# AE402FA0E5597LE0_CM55_HE_View register map
Vendor: Alif Semiconductor; Series: E4; File version: 1.0
CPU: CM55 r1p0, selectable endian, MPU, FPU, double-precision FPU, DSP, VTOR, 8 interrupt priority bits, 1 SAU regions
Registers are 32-bit, read-write, reset 0x0 unless marked. A register's access mark holds for its fields unless they carry their own. Offsets are from the block's base; [hi:lo] are bit positions; 'fields as' and 'values as' point back to an identical list.

## LPI2C1
Base 0x43005000
Same registers: I2C0 0x49010000, I2C1 0x49011000, I2C2 0x49012000, I2C3 0x49013000
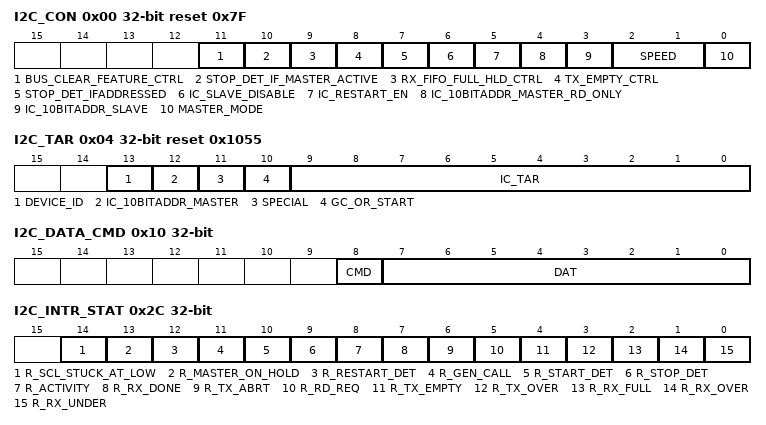
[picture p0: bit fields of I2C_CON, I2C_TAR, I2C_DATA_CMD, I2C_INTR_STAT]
0x00 I2C_CON reset 0x7F — Control Register
  [11] BUS_CLEAR_FEATURE_CTRL — In master mode: In slave mode, this bit is not applicable.
    0=Bus clear feature is disabled; 1=Bus clear feature is enabled
  [10] STOP_DET_IF_MASTER_ACTIVE ro — In master mode, this bit controls whether the I2C issues the STOP_DET interrupt only when master is active or always.
    0=Master issues the STOP_DET interrupt regardless of whether it is active or not; 1=Master issues the STOP_DET interrupt only when active
  [9] RX_FIFO_FULL_HLD_CTRL ro — This bit controls whether the I2C holds the bus when the Rx FIFO is completely full (until data is read out and there is space available in the buffer), or if the Rx FIFO overflows.
    0=Overflow when RX_FIFO is full; 1=Hold bus when RX_FIFO is full
  [8] TX_EMPTY_CTRL — This bit controls the generation of the TX_EMPTY interrupt, as described in the I2C_RAW_INTR_STAT[TX_EMPTY] bit field.
    0=Default behaviour of TX_EMPTY interrupt; 1=Controlled generation of TX_EMPTY interrupt
  [7] STOP_DET_IFADDRESSED — In slave mode, this bit controls whether the I2C issues the STOP_DET interrupt only when slave is addressed or always. Note: During a General Call address, the I2C slave does not issue the STOP_DET interrupt if STOP_DET_IFADDRESSED = 1, even if the I2C slave responds to the General Call address by generating an ACK. The STOP_DET interrupt is issued only when the transmitted address matches the I2C slave address (I2C_SAR).
    0=Slave issues the STOP_DET interrupt regardless of whether it is addressed or not; 1=Slave issues the STOP_DET interrupt only when addressed
  [6] IC_SLAVE_DISABLE — This bit controls whether the I2C has its slave mode enabled or disabled. At reset, I2C slave mode is disabled. Note: Software should ensure that, if this bit is set to 0, then the MASTER_MODE bit is also set to 0 (to ensure proper operation in slave mode).
    0=Slave mode is enabled; 1=Slave mode is disabled
  [5] IC_RESTART_EN — Determines whether RESTART conditions may be sent when acting as a master. Some older slaves do not support handling RESTART conditions; however, RESTART conditions are used in several I2C operations. When RESTART is disabled, the master is prohibited from performing the following functions: - Sending a START BYTE - Performing any high-speed mode operation - Performing direction changes in combined format mode - Performing a read operation with a 10-bit address By replacing RESTART condition followed by STOP and subsequent START condition, split operations are broken down into multiple I2C transfers. If the above operations are performed, it will result in asserting the I2C_RAW_INTR_STAT[TX_ABRT] bit.
    0=Master restart disabled; 1=Master restart enabled
  [4] IC_10BITADDR_MASTER_RD_ONLY ro — For I2C[0-3]: This bit is named IC_10BITADDR_MASTER_RD_ONLY. The function of this bit is handled by the corresponding bit [12] IC_10BITADDR_MASTER in the I2C_TAR register, so this bit is just a read-only copy. For LPI2C1: This bit is named IC_10BITADDR_MASTER. It controls whether the I2C starts its transfers in 7- or 10-bit addressing mode when acting as a master. NOTE: Access type is: R for I2C[0-3]; R/W for LPI2C1.
    0=7-bit master addressing mode; 1=10-bit master addressing mode
  [3] IC_10BITADDR_SLAVE — When acting as a slave, this bit controls whether the I2C responds to 7-bit or 10-bit addresses.
    0=7-bit slave addressing mode. The I2C ignores transactions that involve 10-bit addressing; only the lower 7 bits of I2C_SAR register are compared.; 1=10-bit slave addressing mode. The I2C responds only to 10-bit addressing transfers that match the full 10 bits of I2C_SAR register.
  [2:1] SPEED — These bits control at which speed the I2C operates; its setting is relevant only if the I2C operates in Master mode. Hardware protects against illegal values being programmed by software. These bits must be programmed appropriately for Slave mode also, as they are used to capture correct value of spike filter as per the speed mode. This register should be programmed only with a value in the range of 1 to 3.
    1=Standard mode of operation; 2=Fast or Fast Plus mode of operation; 3=High-speed mode of operation
  [0] MASTER_MODE — This bit controls whether the I2C has its master mode enabled or disabled. At reset, I2C master mode is enabled. Note: Software should ensure that, if this bit is set to 1, then the IC_SLAVE_DISABLE bit is also set to 1 (to ensure proper operation in master mode).
    0=Master mode is disabled; 1=Master mode is enabled
0x04 I2C_TAR reset 0x1055 — Target Address Register
  [13] DEVICE_ID — If bit [11] SPECIAL = 1, then this bit controls whether a Device-ID transfer of a particular slave targeted in the [9-0] IC_TAR field is to be performed by the I2C master.
    0=Disables programming of Device-ID transmission. A Device-ID transfer is not performed and I2C checks bit [10] GC_OR_START to perform either a General Call, or a START BYTE command.; 1=Enables programming of Device-ID transmission. A Device-ID transfer is performed and data bytes based on the number of read commands in the Tx FIFO are received from the targeted slave and put in the Rx FIFO.
  [12] IC_10BITADDR_MASTER — For I2C[0-3]: This bit is named IC_10BITADDR_MASTER. It controls whether the I2C starts its transfers in 7-bit or 10-bit addressing mode, when acting as a master. For LPI2C1: This bit is named IC_10BITADDR_MASTER_RD_ONLY. The function of this bit is handled by the corresponding bit [4] IC_10BITADDR_MASTER in the I2C_CON register, so this bit is just a read-only copy. NOTE: Access type is: R/W for I2C[0-3]; R for LPI2C1.
    values as I2C_CON.IC_10BITADDR_MASTER_RD_ONLY
  [11] SPECIAL — This bit controls whether software performs a special command: Device-ID, or General Call, or START BYTE.
    0=Disables programming of special I2C command. I2C ignores bit [13] DEVICE_ID and bit [10] GC_OR_START and uses the [9-0] IC_TAR field normally.; 1=Enables programming of special I2C command. I2C performs a special command as specified in bit [13] DEVICE_ID or bit [10] GC_OR_START.
  [10] GC_OR_START — If bit [11] SPECIAL = 1 and bit [13] DEVICE_ID = 0, then this bit controls whether I2C performs a General Call or a START BYTE command. Note: After issuing a General Call, only writes may be performed. Attempting to issue a read command results in setting I2C_RAW_INTR_STAT[TX_ABRT] bit. The I2C remains in General Call mode until the SPECIAL bit value is cleared.
    0=General Call transmission; 1=START BYTE transmission
  [9:0] IC_TAR — This is the target address for any I2C master transaction. When transmitting a General Call, these bits are ignored. To generate a START BYTE command, the CPU needs to write into these bits only once. If I2C_TAR[IC_TAR] and I2C_SAR[IC_SAR] are the same, loopback exists but the FIFOs are shared between master and slave, so full loopback is not feasible. Only one direction loopback mode is supported (simplex); duplex is not supported. A master cannot transmit to itself; it can only transmit to a slave. Note: The correct operation of the I2C interface is not guaranteed if this field is programmed to any of the reserved values listed in Table 1-7.
0x08 I2C_SAR reset 0x55 — Slave Address Register
  [9:0] IC_SAR — This register holds the slave address when the I2C is operating as a slave. For 7-bit addressing, only bits [6-0] are used. This register can only be written when the I2C module is disabled, which corresponds to the I2C_ENABLE[ENABLE] bit being set to 0. Writes at other times have no effect. Note: The correct operation of the I2C interface is not guaranteed if this field is programmed to any of the reserved values listed in Table 1-7.
0x0C I2C_HS_MADDR reset 0x1 — High Speed Master Mode Code Address Register
  [2:0] IC_HS_MAR — This bit field holds the value of the I2C HS mode master code. HS mode master codes are reserved 8-bit codes (00001xxx) that are not used for slave addressing or other purposes. Each master has its unique master code; up to eight high-speed mode masters can be present on the same I^2C bus system. Valid values are 0-7. This register can only be written when the I2C module is disabled, which corresponds to the I2C_ENABLE[ENABLE] bit being set to 0. Writes at other times have no effect.
0x10 I2C_DATA_CMD — Rx/Tx Data Buffer and Command Register
  [8] CMD wo — This bit controls whether a read or a write is performed. This bit does not control the direction of data transfer when I2C acts as a slave; it controls the direction only when I2C acts as a master. When a command is entered in the Tx FIFO, this bit distinguishes the write and read commands. In the slave-receiver mode, this bit is a 'don't care' because writes to this register are not required. In the slave-transmitter mode, a 0 in this bit indicates that the data in the [7-0] DAT field is to be transmitted. When programming this bit, consider the following: - Attempting to perform a read operation after sending a General Call command results in the TX_ABRT interrupt (I2C_RAW_INTR_STAT[TX_ABRT] bit) being asserted, unless the I2C_TAR[SPECIAL] bit has been cleared; - If a 1 is written to this bit after receiving RD_REQ interrupt, then TX_ABRT interrupt occurs.
    0=Master write command; 1=Master read command
  [7:0] DAT — This field contains the data to be transmitted or received on the I2C interface. If this field is written while bit [8] CMD = 1, it is ignored by the I2C. If this field is read while bit [8] CMD = 1, it returns the value of the data received on the I2C interface.
0x14 I2C_SS_SCL_HCNT reset 0x190 — Standard Speed SCL High Count Register
  [15:0] IC_SS_SCL_HCNT — This register must be set before any I2C bus transaction can take place to ensure proper I/O timing. It sets the SCL clock high period count for standard speed. This register can only be written when the I2C module is disabled, which corresponds to the I2C_ENABLE[ENABLE] bit being set to 0. Writes at other times have no effect. The minimum valid value is 6; hardware prevents values less than this being written, and if attempted, results in 6 being set. Note: This register must not be programmed to a value higher than 65525, because I2C uses a 16-bit counter to flag an I^2C bus IDLE condition when this counter reaches a value of I2C_SS_SCL_HCNT + 10.
0x18 I2C_SS_SCL_LCNT reset 0x1D6 — Standard Speed SCL Low Count Register
  [15:0] IC_SS_SCL_LCNT — This register must be set before any I2C bus transaction can take place to ensure proper I/O timing. This register sets the SCL clock low period count for standard speed. This register can only be written when the I2C module is disabled, which corresponds to the I2C_ENABLE[ENABLE] bit being set to 0. Writes at other times have no effect. The minimum valid value is 8; hardware prevents values less than this being written, and if attempted, results in 8 being set.
0x1C I2C_FS_SCL_HCNT reset 0x3C — Fast Speed or Fast Mode Plus SCL High Count Register
  [15:0] IC_FS_SCL_HCNT — This register must be set before any I2C bus transaction can take place to ensure proper I/O timing. This register sets the SCL clock high period count for fast speed or fast mode plus. This register can only be written when the I2C module is disabled, which corresponds to the I2C_ENABLE[ENABLE] bit being set to 0. Writes at other times have no effect. The minimum valid value is 6; hardware prevents values less than this being written, and if attempted, results in 6 being set.
0x20 I2C_FS_SCL_LCNT reset 0x82 — Fast Speed or Fast Mode Plus SCL Low Count Register
  [15:0] IC_FS_SCL_LCNT — This register must be set before any I2C bus transaction can take place to ensure proper I/O timing. This register sets the SCL clock low period count for fast speed or fast mode plus. This register can only be written when the I2C module is disabled, which corresponds to the I2C_ENABLE[ENABLE] bit being set to 0. Writes at other times have no effect. The minimum valid value is 8; hardware prevents values less than this being written, and if attempted, results in 8 being set.
0x24 I2C_HS_SCL_HCNT reset 0x6 — High Speed SCL High Count Register
  [15:0] IC_HS_SCL_HCNT — This register must be set before any I2C bus transaction can take place to ensure proper I/O timing. This register sets the SCL clock high period count for high speed. The SCL high time depends on the loading of the bus. For 100 pF loading, the SCL high time is 60 ns. This register can only be written when the I2C module is disabled, which corresponds to the I2C_ENABLE[ENABLE] bit being set to 0. Writes at other times have no effect. The minimum valid value is 6; hardware prevents values less than this being written, and if attempted, results in 6 being set.
0x28 I2C_HS_SCL_LCNT reset 0x10 — High Speed SCL Low Count Register
  [15:0] IC_HS_SCL_LCNT — This register must be set before any I2C bus transaction can take place to ensure proper I/O timing. This register sets the SCL clock low period count for high speed. The SCL low time depends on the loading of the bus. For 100 pF loading, the SCL low time is 160 ns. This register can only be written when the I2C module is disabled, which corresponds to the I2C_ENABLE[ENABLE] bit being set to 0. Writes at other times have no effect. The minimum valid value is 8; hardware prevents values less than this being written, and if attempted, results in 8 being set.
0x2C I2C_INTR_STAT ro — Interrupt Status Register
  [14] R_SCL_STUCK_AT_LOW — For details, see I2C_RAW_INTR_STAT[SCL_STUCK_AT_LOW].
    0=R_SCL_STUCK_AT_LOW interrupt is inactive; 1=R_SCL_STUCK_AT_LOW interrupt is active
  [13] R_MASTER_ON_HOLD — For details, see I2C_RAW_INTR_STAT[MASTER_ON_HOLD]. Note: This interrupt is not supported for LPI2C1 (no dynamic TAR update support).
    0=R_MASTER_ON_HOLD interrupt is inactive; 1=R_MASTER_ON_HOLD interrupt is active
  [12] R_RESTART_DET — For details, see I2C_RAW_INTR_STAT[RESTART_DET]. Note: This interrupt cannot be asserted in this device.
    0=R_RESTART_DET interrupt is inactive; 1=R_RESTART_DET interrupt is active
  [11] R_GEN_CALL — For details, see I2C_RAW_INTR_STAT[GEN_CALL].
    0=R_GEN_CALL interrupt is inactive; 1=R_GEN_CALL interrupt is active
  [10] R_START_DET — For details, see I2C_RAW_INTR_STAT[START_DET].
    0=R_START_DET interrupt is inactive; 1=R_START_DET interrupt is active
  [9] R_STOP_DET — For details, see I2C_RAW_INTR_STAT[STOP_DET].
    0=R_STOP_DET interrupt is inactive; 1=R_STOP_DET interrupt is active
  [8] R_ACTIVITY — For details, see I2C_RAW_INTR_STAT[ACTIVITY].
    0=R_ACTIVITY interrupt is inactive; 1=R_ACTIVITY interrupt is active
  [7] R_RX_DONE — For details, see I2C_RAW_INTR_STAT[RX_DONE].
    0=R_RX_DONE interrupt is inactive; 1=R_RX_DONE interrupt is active
  [6] R_TX_ABRT — For details, see I2C_RAW_INTR_STAT[TX_ABRT].
    0=R_TX_ABRT interrupt is inactive; 1=R_TX_ABRT interrupt is active
  [5] R_RD_REQ — For details, see I2C_RAW_INTR_STAT[RD_REQ].
    0=R_RD_REQ interrupt is inactive; 1=R_RD_REQ interrupt is active
  [4] R_TX_EMPTY — For details, see I2C_RAW_INTR_STAT[TX_EMPTY].
    0=R_TX_EMPTY interrupt is inactive; 1=R_TX_EMPTY interrupt is active
  [3] R_TX_OVER — For details, see I2C_RAW_INTR_STAT[TX_OVER].
    0=R_TX_OVER interrupt is inactive; 1=R_TX_OVER interrupt is active
  [2] R_RX_FULL — For details, see I2C_RAW_INTR_STAT[RX_FULL].
    0=R_RX_FULL interrupt is inactive; 1=R_RX_FULL interrupt is active
  [1] R_RX_OVER — For details, see I2C_RAW_INTR_STAT[RX_OVER].
    0=R_RX_OVER interrupt is inactive; 1=R_RX_OVER interrupt is active
  [0] R_RX_UNDER — For details, see I2C_RAW_INTR_STAT[RX_UNDER].
    0=R_RX_UNDER interrupt is inactive; 1=R_RX_UNDER interrupt is active
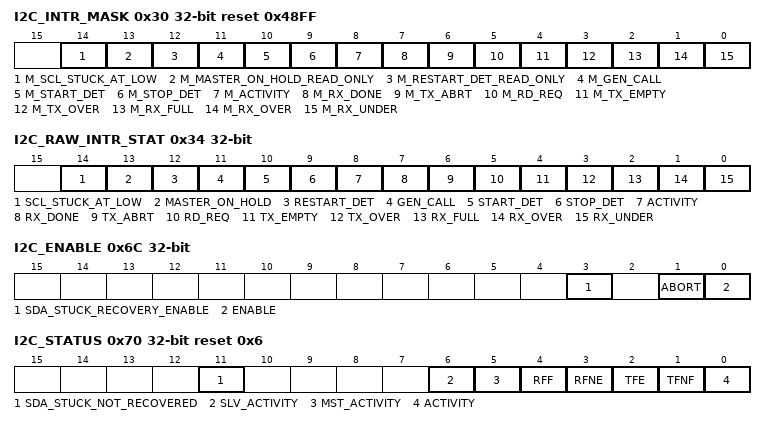
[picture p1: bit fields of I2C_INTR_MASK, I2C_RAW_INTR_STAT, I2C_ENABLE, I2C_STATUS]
0x30 I2C_INTR_MASK reset 0x48FF — Interrupt Mask Register
  [14] M_SCL_STUCK_AT_LOW — Masks the I2C_INTR_STAT[R_SCL_STUCK_AT_LOW] bit.
    0=SCL_STUCK_AT_LOW interrupt is masked; 1=SCL_STUCK_AT_LOW interrupt is unmasked
  [13] M_MASTER_ON_HOLD_READ_ONLY ro — Masks the I2C_INTR_STAT[R_MASTER_ON_HOLD] bit. Note: This interrupt is not supported for LPI2C1 (no dynamic TAR update support).
    0=MASTER_ON_HOLD interrupt is masked; 1=MASTER_ON_HOLD interrupt is unmasked
  [12] M_RESTART_DET_READ_ONLY ro — Masks the I2C_INTR_STAT[R_RESTART_DET] bit. Note: This interrupt cannot be enabled in this device.
    0=RESTART_DET interrupt is masked; 1=RESTART_DET interrupt is unmasked
  [11] M_GEN_CALL — Masks the I2C_INTR_STAT[R_GEN_CALL] bit.
    0=GEN_CALL interrupt is masked; 1=GEN_CALL interrupt is unmasked
  [10] M_START_DET — Masks the I2C_INTR_STAT[R_START_DET] bit.
    0=START_DET interrupt is masked; 1=START_DET interrupt is unmasked
  [9] M_STOP_DET — Masks the I2C_INTR_STAT[R_STOP_DET] bit.
    0=STOP_DET interrupt is masked; 1=STOP_DET interrupt is unmasked
  [8] M_ACTIVITY — Masks the I2C_INTR_STAT[R_ACTIVITY] bit.
    0=ACTIVITY interrupt is masked; 1=ACTIVITY interrupt is unmasked
  [7] M_RX_DONE — Masks the I2C_INTR_STAT[R_RX_DONE] bit.
    0=RX_DONE interrupt is masked; 1=RX_DONE interrupt is unmasked
  [6] M_TX_ABRT — Masks the I2C_INTR_STAT[R_TX_ABRT] bit.
    0=TX_ABRT interrupt is masked; 1=TX_ABRT interrupt is unmasked
  [5] M_RD_REQ — Masks the I2C_INTR_STAT[R_RD_REQ] bit.
    0=RD_REQ interrupt is masked; 1=RD_REQ interrupt is unmasked
  [4] M_TX_EMPTY — Masks the I2C_INTR_STAT[R_TX_EMPTY] bit.
    0=TX_EMPTY interrupt is masked; 1=TX_EMPTY interrupt is unmasked
  [3] M_TX_OVER — Masks the I2C_INTR_STAT [R_TX_OVER] bit.
    0=TX_OVER interrupt is masked; 1=TX_OVER interrupt is unmasked
  [2] M_RX_FULL — Masks the I2C_INTR_STAT[R_RX_FULL] bit.
    0=RX_FULL interrupt is masked; 1=RX_FULL interrupt is unmasked
  [1] M_RX_OVER — Masks the I2C_INTR_STAT[R_RX_OVER] bit.
    0=RX_OVER interrupt is masked; 1=RX_OVER interrupt is unmasked
  [0] M_RX_UNDER — Masks the I2C_INTR_STAT[R_RX_UNDER] bit.
    0=RX_UNDER interrupt is masked; 1=RX_UNDER interrupt is unmasked
0x34 I2C_RAW_INTR_STAT ro — Raw Interrupt Status Register
  [14] SCL_STUCK_AT_LOW — Indicates whether the SCL line is stuck at low for I2C_SCL_STUCK_AT_LOW_TIMEOUT number of IC_CLK periods.
    0=SCL_STUCK_AT_LOW interrupt is inactive; 1=SCL_STUCK_AT_LOW interrupt is active
  [13] MASTER_ON_HOLD — Indicates whether master is holding the bus and Tx FIFO is empty. Note: This interrupt is not supported for LPI2C1 (no dynamic TAR update support).
    0=MASTER_ON_HOLD interrupt is inactive; 1=MASTER_ON_HOLD interrupt is active
  [12] RESTART_DET — Indicates whether a RESTART condition has occurred on the I^2C interface when I2C is operating in slave mode and the slave is being addressed. Note: This interrupt cannot be set in this device.
    0=RESTART_DET interrupt is inactive; 1=RESTART_DET interrupt is active
  [11] GEN_CALL — This bit is set only when a General Call address is received and it is acknowledged. It stays set until it is cleared either by disabling I2C or when the CPU reads bit 0 of the I2C_CLR_GEN_CALL register. The I2C stores the received data in the Rx FIFO.
    0=GEN_CALL interrupt is inactive; 1=GEN_CALL interrupt is active
  [10] START_DET — Indicates whether a START or RESTART condition has occurred on the I2C interface regardless of whether I2C is operating in slave or master mode.
    0=START_DET interrupt is inactive; 1=START_DET interrupt is active
  [9] STOP_DET — Indicates whether a STOP condition has occurred on the I^2C interface regardless of whether I2C is operating in slave or master mode. In slave mode: - If I2C_CON[STOP_DET_IFADDRESSED] = 0, this interrupt is issued regardless of whether the I2C slave is addressed or not. - If I2C_CON[STOP_DET_IFADDRESSED] = 1, this interrupt is issued only if the I2C slave is addressed. Note: During a General Call address, the I2C slave does not issue the STOP_DET interrupt if STOP_DET_IFADDRESSED = 1, even if the I2C slave responds to the General Call address by generating an ACK. The STOP_DET interrupt is issued only when the transmitted address matches the I2C slave address (I2C_SAR). In master mode: - If I2C_CON[STOP_DET_IF_MASTER_ACTIVE] = 0, this interrupt is issued regardless of whether the I2C master is active or not. - If I2C_CON[STOP_DET_IF_MASTER_ACTIVE] = 1, this interrupt is issued only if the I2C master is active.
    0=STOP_DET interrupt is inactive; 1=STOP_DET interrupt is active
  [8] ACTIVITY — This bit captures I2C activity and stays set until it is cleared. There are four ways to clear it: - Disabling the I2C - Reading the I2C_CLR_ACTIVITY register - Reading the I2C_CLR_INTR register - System reset Once this bit is set, it stays set unless one of the four methods is used to clear it. Even if the I2C module is idle, this bit remains set until cleared, indicating that there was activity on the bus.
    0=RAW_INTR_ACTIVITY interrupt is inactive; 1=RAW_INTR_ACTIVITY interrupt is active
  [7] RX_DONE — When the I2C is acting as a slave-transmitter, this bit is set to 1 if the remote master does not acknowledge a transmitted byte. This occurs on the last byte of the transmission, indicating that the transmission is done.
    0=RX_DONE interrupt is inactive; 1=RX_DONE interrupt is active
  [6] TX_ABRT — This bit indicates if the I2C, acting as a transmitter on the I^2C bus, is unable to complete the intended actions on the contents of the Tx FIFO. This situation can occur both as an I^2C master or an I^2C slave, and is referred to as a transmit abort. When this bit is set to 1, the I2C_TX_ABRT_SOURCE register indicates the reason why the transmit abort has occured. The I2C flushes/resets/empties both the Tx FIFO and the Rx FIFO whenever there is a transmit abort caused by any of the events tracked by the I2C_TX_ABRT_SOURCE register. The FIFOs remain in this flushed state until the I2C_CLR_TX_ABRT register is read. Once this read is performed, the FIFOs are ready to accept more data bytes.
    0=TX_ABRT interrupt is inactive; 1=TX_ABRT interrupt is active
  [5] RD_REQ — This bit is set to 1 when the I2C is acting as a slave and another I^2C master is attempting to read data from I2C. The I2C holds the bus in a wait state until this interrupt is serviced, which means that the slave has been addressed by a remote master asking for data to be transferred. CPU must respond to this interrupt and then write the requested data to the I2C_DATA_CMD register. This bit is cleared just after the CPU reads the I2C_CLR_RD_REQ register.
    0=RD_REQ interrupt is inactive; 1=RD_REQ interrupt is active
  [4] TX_EMPTY — The behavior of the TX_EMPTY interrupt status differs based on the selection in the I2C_CON[TX_EMPTY_CTRL] bit. When I2C_CON[TX_EMPTY_CTRL] = 0: This bit is set to 1 when the transmit FIFO buffer is at or below the threshold value set in the I2C_TX_TL register. When I2C_CON[TX_EMPTY_CTRL] = 1: This bit is set to 1 when the transmit FIFO buffer is at or below the threshold value set in the I2C_TX_TL register and the transmission of the address/data from the internal shift register for the most recently popped command is completed. This bit is automatically cleared by hardware when the transmit buffer level goes above the threshold. If the module is disabled (I2C_ENABLE[ENABLE] = 0), the Tx FIFO is flushed and held in reset; therefore, the Tx FIFO looks like it has no data within it, so this bit is set to 1, provided there is activity in the master or slave state machines. When there is no longer any activity and I2C_ENABLE_STATUS[IC_EN] goes to 0, this bit is cleared.
    0=TX_EMPTY interrupt is inactive; 1=TX_EMPTY interrupt is active
  [3] TX_OVER — Set during transmit if the transmit buffer is completely full and the processor attempts to issue another I2C command by writing to the I2C_DATA_CMD register. If the module is disabled (I2C_ENABLE[ENABLE] = 0), this bit keeps its level until the master or slave state machines go into IDLE, and when the I2C_ENABLE_STATUS[IC_EN] bit goes to 0, this interrupt is cleared.
    0=TX_OVER interrupt is inactive; 1=TX_OVER interrupt is active
  [2] RX_FULL — Set when the receive buffer reaches or goes above the threshold level in the I2C_RX_TL register. This bit is automatically cleared by hardware when the receive buffer level goes below the threshold. If the module is disabled (I2C_ENABLE[ENABLE] = 0), the Rx FIFO is flushed and held in reset; therefore, the Rx FIFO is not full. So, this bit is cleared once the I2C_ENABLE[ENABLE] bit is programmed to 0, regardless of the activity that continues.
    0=RX_FULL interrupt is inactive; 1=RX_FULL interrupt is active
  [1] RX_OVER — Set if the receive buffer is completely full and an additional byte is received from an external I^2C device. The I2C acknowledges this, but any data bytes received after the Rx FIFO is full are lost. If the module is disabled (I2C_ENABLE[ENABLE] = 0), this bit keeps its level until the master or slave state machines go into IDLE, and when the I2C_ENABLE_STATUS[IC_EN] bit goes to 0, this interrupt is cleared.
    0=RX_OVER interrupt is inactive; 1=RX_OVER interrupt is active
  [0] RX_UNDER — Set if the processor attempts to read the receive buffer when it is empty by reading from the I2C_DATA_CMD register. If the module is disabled (I2C_ENABLE[ENABLE] = 0), this bit keeps its level until the master or slave state machines go into IDLE, and when the I2C_ENABLE_STATUS[IC_EN] bit goes to 0, this interrupt is cleared.
    0=RX_UNDER interrupt is inactive; 1=RX_UNDER interrupt is active
0x38 I2C_RX_TL — Receive FIFO Threshold Register
  [7:0] RX_TL — Controls the level of entries (or above) that triggers the RX_FULL interrupt (I2C_RAW_INTR_STAT[RX_FULL] bit). Valid range is 0-31 (Rx FIFO depth = 32). Hardware does not allow this field to be set to a value larger than the depth of the buffer; any attempt to do so results in a value of 31 being set. A value of 0 sets the threshold for 1 entry, and a value of 31 sets the threshold for 32 entries.
0x3C I2C_TX_TL — Transmit FIFO Threshold Register
  [7:0] TX_TL — Controls the level of entries (or below) that triggers the TX_EMPTY interrupt (I2C_RAW_INTR_STAT[TX_EMPTY]). Valid range is 0-31 (Tx FIFO depth = 32). Hardware does not allow this field to be set to a value larger than the depth of the buffer; any attempt to do so results in a value of 31 being set. A value of 0 sets the threshold for 0 entries, and a value of 31 sets the threshold for 31 entries.
0x40 I2C_CLR_INTR ro — Clear Combined and Individual Interrupt Register
  [0] CLR_INTR — Read this bit to: - Clear the combined interrupt; - Clear all individual interrupts; - Clear the I2C_TX_ABRT_SOURCE register; This bit does not clear hardware clearable interrupts but software clearable interrupts. Refer to I2C_TX_ABRT_SOURCE[ABRT_SBYTE_NORSTRT] bit for an exception to clearing it.
0x44 I2C_CLR_RX_UNDER ro — Clear RX_UNDER Interrupt Register
  [0] CLR_RX_UNDER — Read this bit to clear the I2C_RAW_INTR_STAT[RX_UNDER] bit.
0x48 I2C_CLR_RX_OVER ro — Clear RX_OVER Interrupt Register
  [0] CLR_RX_OVER — Read this bit to clear the I2C_RAW_INTR_STAT[RX_OVER] bit.
0x4C I2C_CLR_TX_OVER ro — Clear TX_OVER Interrupt Register
  [0] CLR_TX_OVER — Read this bit to clear the I2C_RAW_INTR_STAT[TX_OVER] bit.
0x50 I2C_CLR_RD_REQ ro — Clear RD_REQ Interrupt Register
  [0] CLR_RD_REQ — Read this bit to clear the I2C_RAW_INTR_STAT[RD_REQ] bit.
0x54 I2C_CLR_TX_ABRT ro — Clear TX_ABRT Interrupt Register
  [0] CLR_TX_ABRT — Read this bit to clear the I2C_RAW_INTR_STAT[TX_ABRT] bit, and the I2C_TX_ABRT_SOURCE register. This also releases the Tx FIFO from the flushed/reset state, allowing more writes to the Tx FIFO. Refer to I2C_TX_ABRT_SOURCE[ABRT_SBYTE_NORSTRT] bit for an exception to clearing it.
0x58 I2C_CLR_RX_DONE ro — Clear RX_DONE Interrupt Register
  [0] CLR_RX_DONE — Read this bit to clear the I2C_RAW_INTR_STAT[RX_DONE] bit.
0x5C I2C_CLR_ACTIVITY ro — Clear ACTIVITY Interrupt Register
  [0] CLR_ACTIVITY — Reading this bit clears the ACTIVITY interrupt if the I2C is not active anymore. If the I2C is still active on the bus, the ACTIVITY interrupt bit continues to be set. It is automatically cleared by hardware if the I2C is disabled and if there is no further activity on the bus.
0x60 I2C_CLR_STOP_DET ro — Clear STOP_DET Interrupt Register
  [0] CLR_STOP_DET — Read this bit to clear the I2C_RAW_INTR_STAT[STOP_DET] bit.
0x64 I2C_CLR_START_DET ro — Clear START_DET Interrupt Register
  [0] CLR_START_DET — Read this bit to clear the I2C_RAW_INTR_STAT[START_DET] bit.
0x68 I2C_CLR_GEN_CALL ro — Clear GEN_CALL Interrupt Register
  [0] CLR_GEN_CALL — Read this bit to clear the I2C_RAW_INTR_STAT[GEN_CALL] bit.
0x6C I2C_ENABLE — Enable Register
  [3] SDA_STUCK_RECOVERY_ENABLE — If SDA is stuck at low, as indicated through the TX_ABRT interrupt (I2C_TX_ABRT_SOURCE[ABRT_SDA_STUCK_AT_LOW] bit asserted), then this bit is used as a control knob to initiate the SDA recovery mechanism (that is, send at most 9 SCL clocks and STOP to release the SDA line), and then this bit gets auto cleared.
    0=Master disables the SDA stuck at low recovery mechanism; 1=Master initiates the SDA stuck at low recovery mechanism
  [1] ABORT — When set, the controller initiates the transfer abort. Software can abort the I2C transfer in master mode by setting this bit. Software can set this bit only when the ENABLE bit is already set; otherwise, the controller ignores any write to the ABORT bit. Software cannot clear the ABORT bit once set. In response to an ABORT, the controller issues a STOP and flushes the Tx FIFO after completing the current transfer, then sets the TX_ABRT interrupt after the abort operation. The ABORT bit is cleared automatically after the abort operation.
    0=ABORT operation not in progress; 1=ABORT operation in progress
  [0] ENABLE — Controls whether the I2C module is enabled or disabled. Software can disable the I2C module while it is active. However, it is important that care be taken to ensure that the I2C module is disabled properly. A recommended procedure is described in Section Disabling the I2C. When I2C is disabled, the following occurs: - Tx FIFO and Rx FIFO get flushed; - I2C_INTR_STAT status bits are still active until I2C goes IDLE; If the I2C is transmitting, it stops as well as deletes the contents of the transmit buffer after the current transfer is complete. If the I2C is receiving, it stops the current transfer at the end and does not acknowledge the transfer.
    0=Disables I2C; 1=Enables I2C
0x70 I2C_STATUS ro reset 0x6 — Status Register
  [11] SDA_STUCK_NOT_RECOVERED — This bit indicates that SDA stuck at low is not recovered after the SDA recovery mechanism. In slave mode, this bit is not applicable.
    0=SDA stuck at low is recovered after recovery mechanism; 1=SDA stuck at low is not recovered after recovery mechanism
  [6] SLV_ACTIVITY — Slave FSM Activity Status.
    0=Slave FSM is in IDLE state (slave is not active); 1=Slave FSM is not in IDLE state (slave is active)
  [5] MST_ACTIVITY — Master FSM Activity Status.
    0=Master FSM is in IDLE state (master is not active); 1=Master FSM is not in IDLE state (master is active)
  [4] RFF — Receive FIFO Completely Full. When the Rx FIFO is completely full, this bit is set. When the Rx FIFO contains one or more empty locations, this bit is cleared.
    0=Rx FIFO not full; 1=Rx FIFO is full
  [3] RFNE — Receive FIFO Not Empty. When the Rx FIFO contains one or more valid entries, this bit is set. When the Rx FIFO is empty, this bit is cleared.
    0=Rx FIFO is empty; 1=Rx FIFO not empty
  [2] TFE — Transmit FIFO Completely Empty. When the Tx FIFO is completely empty, this bit is set. When the Tx FIFO contains one or more valid entries, this bit is cleared.
    0=Tx FIFO not empty; 1=Tx FIFO is empty
  [1] TFNF — Transmit FIFO Not Full. When the Tx FIFO contains one or more empty locations, this bit is set. When the Tx FIFO is full, this bit is cleared.
    0=Tx FIFO is full; 1=Tx FIFO not full
  [0] ACTIVITY — I2C Activity Status. This bit is an OR of bit [5] MST_ACTIVITY and bit [6] SLV_ACTIVITY.
    0=I2C is IDLE; 1=I2C is active
0x74 I2C_TXFLR ro — Transmit FIFO Level Register
  [5:0] TXFLR — Tx FIFO Level. Contains the number of valid data entries in the Tx FIFO.
0x78 I2C_RXFLR ro — Receive FIFO Level Register
  [5:0] RXFLR — Rx FIFO Level. Contains the number of valid data entries in the Rx FIFO.
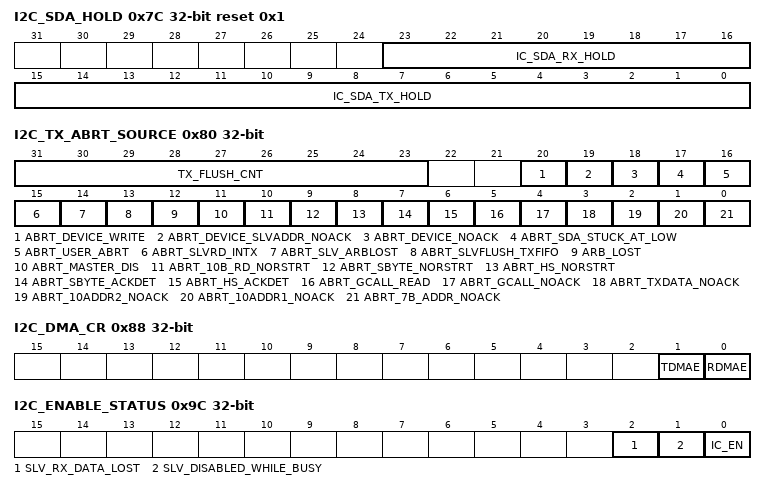
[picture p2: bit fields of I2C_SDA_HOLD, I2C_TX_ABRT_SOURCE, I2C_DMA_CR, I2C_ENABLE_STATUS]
0x7C I2C_SDA_HOLD reset 0x1 — SDA Hold Time Length Register
  [23:16] IC_SDA_RX_HOLD — Sets the required SDA hold time in units of IC_CLK period, when I2C acts as a receiver.
  [15:0] IC_SDA_TX_HOLD — Sets the required SDA hold time in units of IC_CLK period, when I2C acts as a transmitter.
0x80 I2C_TX_ABRT_SOURCE ro — Transmit Abort Source Register
  [31:23] TX_FLUSH_CNT — This bit is applicable in both master and slave mode. This field indicates the number of Tx FIFO data commands which are flushed due to TX_ABRT interrupt. It is cleared whenever I2C is disabled. Role of I2C: Master-Transmitter or Slave-Transmitter
  [20] ABRT_DEVICE_WRITE — This is a master-mode-only bit. This field indicates that the master has initiated Device-ID transfer and the Tx FIFO consists of write commands. Role of I2C: Master
    0=This abort is not generated; 1=Device-ID transfer initiated and Tx FIFO with write commands
  [19] ABRT_DEVICE_SLVADDR_NOACK — This is a master-mode-only bit. This field indicates that the master has initiated Device-ID transfer and the slave address sent was not acknowledged by any slave. Role of I2C: Master
    0=This abort is not generated; 1=Slave address not acknowledged by any slave
  [18] ABRT_DEVICE_NOACK — This is a master-mode-only bit. This field indicates that the master has initiated Device-ID transfer and the Device-ID sent was not acknowledged by any slave. Role of I2C: Master
    0=This abort is not generated; 1=Device-ID not acknowledged by any slave
  [17] ABRT_SDA_STUCK_AT_LOW — This is a master-mode-only bit. The field indicates that the master has detected the SDA stuck at low for the I2C_SDA_STUCK_AT_LOW_TIMEOUT number of IC_CLK cycles. Role of I2C: Master
    0=This abort is not generated; 1=SDA stuck at low for the I2C_SDA_STUCK_AT_LOW_TIMEOUT number of IC_CLK cycles
  [16] ABRT_USER_ABRT — This is a master-mode-only bit. This field indicates that the master has detected a transfer abort (initiated by setting I2C_ENABLE[ABORT] = 1). Role of I2C: Master-Transmitter
    0=This abort is not generated; 1=Transfer abort detected by master
  [15] ABRT_SLVRD_INTX — This is a slave-mode-only bit. When the processor side responds to a slave request for data to be transmitted to a remote master and the user writes a 1 in the I2C_DATA_CMD[CMD] bit. Role of I2C: Slave-Transmitter
    0=This abort is not generated; 1=Slave trying to transmit to remote master in read mode
  [14] ABRT_SLV_ARBLOST — This is a slave-mode-only bit. This field indicates that a slave has lost the bus while transmitting data to a remote master. The ARB_LOST bit in this register is set at the same time. Note: Even though the slave never 'owns' the bus, something could go wrong on the bus. This is a fail-safe check. For instance, during a data transmission at the low-to-high transition of SCL, if what is on the data bus is not what is supposed to be transmitted, then the I2C no longer 'owns' the bus. Role of I2C: Slave-Transmitter
    0=This abort is not generated; 1=Slave lost arbitration to remote master
  [13] ABRT_SLVFLUSH_TXFIFO — This is a slave-mode-only bit. This field specifies that the slave has received a read command and some data exists in the Tx FIFO, so the slave issues TX_ABRT interrupt to flush old data in the Tx FIFO. Role of I2C: Slave-Transmitter
    0=This abort is not generated; 1=Slave flushes existing data in the Tx FIFO upon getting a read command
  [12] ARB_LOST — This bit is applicable in both master and slave mode. This field specifies that the master has lost arbitration, or if the ABRT_SLV_ARBLOST bit in this register is also set, then the slave-transmitter has lost arbitration. Role of I2C: Master-Transmitter or Slave-Transmitter
    0=This abort is not generated; 1=Master-transmitter or slave-transmitter lost arbitration
  [11] ABRT_MASTER_DIS — This is a master-mode-only bit. This field indicates that the user tries to initiate a master operation with the master mode disabled. Role of I2C: Master-Transmitter or Master-Receiver operation when master mode disabled
    0=This abort is not generated; 1=User initiating master
  [10] ABRT_10B_RD_NORSTRT — This is a master-mode-only bit. This field indicates that the RESTART feature is disabled (I2C_CON[IC_RESTART_EN] = 0) and the master sends a read command in 10-bit addressing mode. Role of I2C: Master-Receiver
    0=This abort is not generated; 1=Master read in 10-bit addressing mode when the RESTART feature is disabled
  [9] ABRT_SBYTE_NORSTRT — This is a master-mode-only bit. This field indicates that the RESTART feature is disabled (I2C_CON[IC_RESTART_EN] = 0) and the user is tryingto send a START BYTE. To clear the ABRT_SBYTE_NORSTRT bit, the source of this abort must be fixed first: - Restart must be enabled (I2C_CON[IC_RESTART_EN] = 1); - I2C_TAR[SPECIAL] bit must be cleared; OR - I2C_TAR[GC_OR_START] bit must be cleared; Once the source of the ABRT_SBYTE_NORSTRT abort is fixed, then this bit is cleared in the same manner as other bits in this register. If the source of this abort is not fixed before attempting to clear this bit, the bit clears for one cycle and then gets reasserted. Role of I2C: Master trying to send START BYTE when RESTART disabled
    0=This abort is not generated; 1=User
  [8] ABRT_HS_NORSTRT — This is a master-mode-only bit. This field indicates that the RESTART feature is disabled (I2C_CON[IC_RESTART_EN] = 0) and the user is tryingto use the master to transfer data in High-Speed mode. Role of I2C: Master-Transmitter or Master-Receiver to switch master to HS mode when the RESTART feature is disabled
    0=This abort is not generated; 1=User trying
  [7] ABRT_SBYTE_ACKDET — This is a master-mode-only bit. This field indicates that the master has sent a START BYTE and the START BYTE was acknowledged (wrong behavior). Role of I2C: Master
    0=This abort is not generated; 1=ACK detected for START BYTE
  [6] ABRT_HS_ACKDET — This is a master-mode-only bit. This field indicates that the master is in High-Speed mode and the High-Speed master code was acknowledged (wrong behavior). Role of I2C: Master acknowledged in HS mode
    0=This abort is not generated; 1=HS master code
  [5] ABRT_GCALL_READ — This is a master-mode-only bit. This field indicates that I2C in master mode has sent a General Call but the user programmed the byte following the General Call to be a read from the bus (I2C_DATA_CMD[CMD] = 1). Role of I2C: Master-Transmitter
    0=This abort is not generated; 1=General Call is followed by read from bus
  [4] ABRT_GCALL_NOACK — This is a master-mode-only bit. This field indicates that I2C in master mode has sent a General Call and no slave on the bus acknowledged the General Call. Role of I2C: Master-Transmitter
    0=This abort is not generated; 1=General Call not acknowledged by any slave
  [3] ABRT_TXDATA_NOACK — This is a master-mode-only bit. This field indicates that the master received an acknowledgment for the address, but when the master sent data byte(s) following the address, it did not receive an acknowledgment from remote slave(s). Role of I2C: Master-Transmitter
    0=This abort is not generated; 1=Transmitted data not acknowledged by addressed slave
  [2] ABRT_10ADDR2_NOACK — This is a master-mode-only bit. This field indicates that the master is in 10-bit address mode and the second address byte was not acknowledged by any slave. Role of I2C: Master-Transmitter or Master-Receiver
    0=This abort is not generated; 1=Byte 2 of 10-bit address not acknowledged by any slave
  [1] ABRT_10ADDR1_NOACK — This is a master-mode-only bit. This field indicates that the master is in 10-bit address mode and the first address byte was not acknowledged by any slave. Role of I2C: Master-Transmitter or Master-Receiver
    0=This abort is not generated; 1=Byte 1 of 10-bit address not acknowledged by any slave
  [0] ABRT_7B_ADDR_NOACK — This is a master-mode-only bit. This field indicates that the master is in 7-bit addressing mode and the address sent was not acknowledged by any slave. Role of I2C: Master-Transmitter or Master-Receiver
    0=This abort is not generated; 1=7-bit address not acknowledged by any slave
0x88 I2C_DMA_CR — DMA Control Register
  [1] TDMAE — Transmit DMA Enable. This bit enables/disables the Tx FIFO DMA channel.
    0=Tx FIFO DMA channel disabled; 1=Tx FIFO DMA channel enabled
  [0] RDMAE — Receive DMA Enable. This bit enables/disables the Rx FIFO DMA channel.
    0=Rx FIFO DMA channel disabled; 1=Rx FIFO DMA channel enabled
0x8C I2C_DMA_TDLR — DMA Transmit Data Level Register
  [4:0] DMATDL — DMA Transmit Data Level. This bit field controls the level at which a DMA request is made by the transmit logic. It is equal to the watermark level; that is, the DMA_TX_REQ signal is generated when the number of valid data entries in the Tx FIFO is equal to or below this field value, and I2C_DMA_CR[TDMAE] = 1.
0x90 I2C_DMA_RDLR — DMA Receive Data Level Register
  [4:0] DMARDL — DMA Receive Data Level. This bit field controls the level at which a DMA request is made by the receive logic. The watermark level = DMARDL + 1; that is, the DMA_RX_REQ signal is generated when the number of valid data entries in the Rx FIFO is equal to or more than this field value + 1, and I2C_DMA_CR[RDMAE] = 1. For instance, when DMARDL = 0, then DMA_RX_REQ is asserted when one or more data entries are present in the Rx FIFO.
0x94 I2C_SDA_SETUP reset 0x64 — SDA Setup Register
  [7:0] SDA_SETUP — SDA Setup It is recommended that if the required delay is 1000 ns, then for an IC_CLK frequency of 10 MHz, I2C_SDA_SETUP should be programmed to a value of 11. I2C_SDA_SETUP must be programmed with a minimum value of 2.
0x98 I2C_ACK_GENERAL_CALL reset 0x1 — ACK General Call Register
  [0] ACK_GEN_CALL — ACK General Call. When set to 1, I2C responds with a ACK when it receives a General Call. Otherwise, I2C responds with a NACK.
    0=Generates NACK for a General Call; 1=Generates ACK for a General Call
0x9C I2C_ENABLE_STATUS ro — Enable Status Register
  [2] SLV_RX_DATA_LOST — Slave Received Data Lost. This bit indicates if a slave-receiver operation has been aborted with at least one data byte received from an I^2C transfer, due to CPU setting the I2C_ENABLE[ENABLE] bit from 1 to 0. When read as 0, the I2C is deemed to have been disabled without being actively involved in the data phase of slave-receiver transfer. When read as 1, the I2C is deemed to have been actively engaged in an aborted I^2C transfer (with matching address) and the data phase of the I^2C transfer has been entered, even though a data byte has been responded with a NACK. Note: If the remote master terminates the transfer with a STOP condition before the I2C has a chance to NACK the transfer, and the I2C_ENABLE[ENABLE] bit has been set to 0, then this bit is also set to 1. Note: CPU can safely read this bit when the IC_EN bit is read as 0.
    0=Slave Rx data is not lost; 1=Slave Rx data is lost
  [1] SLV_DISABLED_WHILE_BUSY — Slave Disabled While Busy (Transmit, Receive). This bit indicates if a potential or active slave operation has been aborted due to CPU setting the I2C_ENABLE[ENABLE] bit from 1 to 0. This bit is asserted when the CPU writes a 0 to the I2C_ENABLE[ENABLE] bit, while: - In slave-transmitter operation, I2C is receiving the address byte from the remote master; - In slave-receiver operation, I2C is receiving the address and data bytes from the remote master; When read as 0, the I2C is deemed to have been disabled when there is master activity, or when the I^2C bus is IDLE. When read as 1, the I2C is deemed to have forced a NACK during any part of an I^2C transfer, regardless of whether the I^2C address matches the slave address set in I2C (I2C_SAR) OR if the transfer is completed before the I2C_ENABLE[ENABLE] bit is set to 0, but has not taken effect. Note: If the remote master terminates the transfer with a STOP condition before the I2C has a chance to NACK the transfer, and the I2C_ENABLE[ENABLE] bit has been set to 0, then this bit is also set to 1. Note: CPU can safely read this bit when the IC_EN bit is read as 0.
    0=Slave is disabled when it is IDLE; 1=Slave is disabled when it is active
  [0] IC_EN — I2C Enable Status. Note: The CPU can safely read this bit anytime. When this bit is read as 0, the CPU can safely read the SLV_RX_DATA_LOST and SLV_DISABLED_WHILE_BUSY bits.
    0=I2C is deemed completely inactive; 1=I2C is deemed to be in an enabled state
0xA0 I2C_FS_SPKLEN reset 0x5 — SS, FS or FM+ Spike Suppression Limit Register
  [7:0] IC_FS_SPKLEN — This register must be set before any I2C bus transaction can take place to ensure stable operation. This register sets the duration, measured in IC_CLK cycles, of the longest spike in the SCL or SDA lines that will be filtered out by the spike suppression logic. This register can only be written when the I2C module is disabled, which corresponds to the I2C_ENABLE[ENABLE] bit being set to 0. Writes at other times have no effect. The minimum valid value is 1; hardware prevents values less than this being written, and if attempted, results in 1 being set.
0xA4 I2C_HS_SPKLEN reset 0x1 — HS Spike Suppression Limit Register
  [7:0] IC_HS_SPKLEN — This register must be set before any I2C bus transaction can take place to ensure stable operation. This register sets the duration, measured in IC_CLK cycles, of the longest spike in the SCL or SDA lines that will be filtered out by the spike suppression logic. This register can only be written when the I2C module is disabled, which corresponds to the I2C_ENABLE[ENABLE] bit being set to 0. Writes at other times have no effect. The minimum valid value is 1; hardware prevents values less than this being written, and if attempted, results in 1 being set.
0xAC I2C_SCL_STUCK_AT_LOW_TIMEOUT reset 0xFFFFFFFF — SCL Stuck at Low Timeout Register
  [31:0] IC_SCL_STUCK_LOW_TIMEOUT — The I2C generates an interrupt (I2C_RAW_INTR_STAT[SCL_STUCK_AT_LOW]), if it detects the SCL stuck at low for a duration of IC_SCL_STUCK_LOW_TIMEOUT in units of IC_CLK period. This register can only be written when the I2C module is disabled, which corresponds to the I2C_ENABLE[ENABLE] bit being set to 0. Writes at other times have no effect.
0xB0 I2C_SDA_STUCK_AT_LOW_TIMEOUT reset 0xFFFFFFFF — SDA Stuck at Low Timeout Register
  [31:0] IC_SDA_STUCK_LOW_TIMEOUT — The I2C initiates the recovery of the SDA line through enabling the I2C_ENABLE[SDA_STUCK_RECOVERY_EN] bit, if it detects the SDA stuck at low for a duration of IC_SDA_STUCK_LOW_TIMEOUT in units of IC_CLK period.
0xB4 I2C_CLR_SCL_STUCK_DET ro — Clear SCL Stuck at Low Detect Interrupt Register
  [0] CLR_SCL_STUCK_DET — Read this bit to clear the I2C_RAW_INTR_STAT[SCL_STUCK_AT_LOW] bit.
0xB8 I2C_DEVICE_ID ro — Device-ID Register
  [23:0] DEVICE_ID — Contains the Device-ID of the component
0xF0 I2C_REG_TIMEOUT_RST reset 0x8 — Timeout Counter Reset Value Register
  [3:0] REG_TIMEOUT_RST_RW — This field holds the reset value of the register timeout counter. The value of this field (default or programmed) determines from what value the register timeout counter starts counting down. A zero on this counter will break the waited APB transaction with PSLVERR as high.
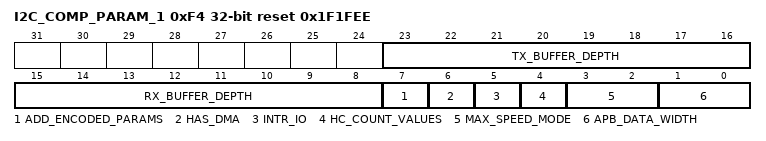
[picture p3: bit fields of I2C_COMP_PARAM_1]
0xF4 I2C_COMP_PARAM_1 ro reset 0x1F1FEE — Component Parameter Register 1
  [23:16] TX_BUFFER_DEPTH — This field defines the Tx FIFO buffer depth.
    31=32 entries
  [15:8] RX_BUFFER_DEPTH — This field defines the Rx FIFO buffer depth.
    31=32 entries
  [7] ADD_ENCODED_PARAMS — This field defines the encoded parameters.
    1=Capability of reading encoded parameters via SW is enabled
  [6] HAS_DMA — This field defines the DMA handshaking.
    1=DMA handshaking signals are enabled
  [5] INTR_IO — This field defines the interrupt output type.
    1=Combined interrupt output
  [4] HC_COUNT_VALUES — This field defines the count values.
    0=Programmable count values for each mode
  [3:2] MAX_SPEED_MODE — This field defines the maximum speed mode.
    3=High-Speed
  [1:0] APB_DATA_WIDTH — This field defines the APB data bus width.
    2=32 bits
0xF8 I2C_COMP_VERSION ro reset 0x3230332A — Component Version Register
  [31:0] IC_COMP_VERSION — Component version
0xFC I2C_COMP_TYPE ro reset 0x44570140 — Component Type Register
  [31:0] IC_COMP_TYPE — Component type
